# PCIE0_DAT register map
Vendor: Texas Instruments
Registers are 32-bit, read-write, reset 0x0 unless marked. A register's access mark holds for its fields unless they carry their own. Offsets are as the file gives them; [hi:lo] are bit positions; {n}, {i} and the like mark numbered series.

## PCIE0_DAT (part 4 of 6)
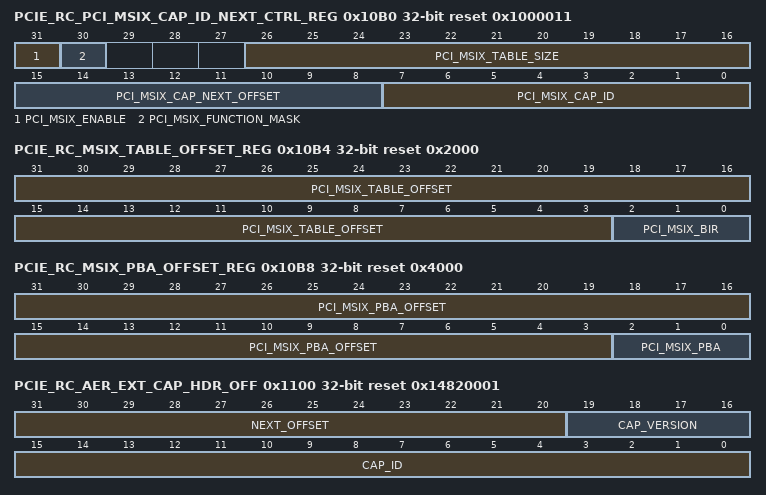
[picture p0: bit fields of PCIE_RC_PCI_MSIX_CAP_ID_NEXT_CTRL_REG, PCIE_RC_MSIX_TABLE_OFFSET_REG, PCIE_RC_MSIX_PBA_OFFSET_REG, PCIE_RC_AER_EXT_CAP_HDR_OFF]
0x10B0 PCIE_RC_PCI_MSIX_CAP_ID_NEXT_CTRL_REG access per field reset 0x1000011 — MSI-X Capability ID, Next Pointer, Control Registers. For a description of this standard PCIe register, see the PCI Express Specification.
  [31] PCI_MSIX_ENABLE rw — MSI-X Enable For a description of this standard PCIe register field, see the PCI Express Specification
  [30] PCI_MSIX_FUNCTION_MASK rw — Function Mask For a description of this standard PCIe register field, see the PCI Express Specification Note: The access attributes of this field are as follows: - Dbi: R/W
  [26:16] PCI_MSIX_TABLE_SIZE ro — MSI-X Table Size For a description of this standard PCIe register field, see the PCI Express Specification SRIOV Note: All VFs in a single PF have the same value for 'MSI-X Table Size' [PCI_MSIX_TABLE_SIZE field in VF_PCI_MSIX_CAP_ID_NEXT_CTRL_REG] To write this common value, you must perform a DBI_CS2 write [that is, assert the dbi_cs2 input, or the CS2 address bit for the AXI bridge] while accessing the PCI_MSIX_TABLE_SIZE field in the PF
  [15:8] PCI_MSIX_CAP_NEXT_OFFSET ro — MSI-X Next Capability Pointer For a description of this standard PCIe register field, see the PCI Express Specification Note: The access attributes of this field are as follows: - Dbi: if [DBI_RO_WR_EN == 1] then R/W else R Note: This register field is sticky
  [7:0] PCI_MSIX_CAP_ID ro — MSI-X Capability ID For a description of this standard PCIe register field, see the PCI Express Specification
0x10B4 PCIE_RC_MSIX_TABLE_OFFSET_REG ro reset 0x2000 — MSI-X Table Offset and BIR Register. For a description of this standard PCIe register, see the PCI Express Specification.
  [31:3] PCI_MSIX_TABLE_OFFSET — MSI-X Table Offset For a description of this standard PCIe register field, see the PCI Express Specification Note: The access attributes of this field are as follows: - Dbi: if [DBI_RO_WR_EN == 1 &amp;&amp; MSIX_CAP_ENABLE=1] then R/W else R Note: This register field is sticky
  [2:0] PCI_MSIX_BIR — MSI-X Table Bar Indicator Register Field For a description of this standard PCIe register field, see the PCI Express Specification Note: The access attributes of this field are as follows: - Dbi: if [DBI_RO_WR_EN == 1 &amp;&amp; MSIX_CAP_ENABLE=1 ] then R/W else R Note: This register field is sticky
0x10B8 PCIE_RC_MSIX_PBA_OFFSET_REG ro reset 0x4000 — MSI-X PBA Offset and BIR Register. For a description of this standard PCIe register, see the PCI Express Specification.
  [31:3] PCI_MSIX_PBA_OFFSET — MSI-X PBA Offset For a description of this standard PCIe register field, see the PCI Express Specification Note: The access attributes of this field are as follows: - Dbi: if [DBI_RO_WR_EN == 1 &amp;&amp; MSIX_CAP_ENABLE=1] then R/W else R Note: This register field is sticky
  [2:0] PCI_MSIX_PBA — MSI-X PBA BIR For a description of this standard PCIe register field, see the PCI Express Specification Note: The access attributes of this field are as follows: - Dbi: if [DBI_RO_WR_EN == 1 &amp;&amp; MSIX_CAP_ENABLE=1] then R/W else R Note: This register field is sticky
0x1100 PCIE_RC_AER_EXT_CAP_HDR_OFF ro reset 0x14820001 — Advanced Error Reporting Extended Capability Header. For a description of this standard PCIe register, see the PCI Express Specification.
  [31:20] NEXT_OFFSET — Next Capability Offset For a description of this standard PCIe register field, see the PCI Express Specification Note: The access attributes of this field are as follows: - Dbi: if [DBI_RO_WR_EN == 1] then R/W[sticky] else R[sticky] Note: This register field is sticky
  [19:16] CAP_VERSION — Capability Version For a description of this standard PCIe register field, see the PCI Express Specification Note: The access attributes of this field are as follows: - Dbi: if [DBI_RO_WR_EN == 1] then R/W[sticky] else R[sticky] Note: This register field is sticky
  [15:0] CAP_ID — AER Extended Capability ID For a description of this standard PCIe register field, see the PCI Express Specification Note: The access attributes of this field are as follows: - Dbi: if [DBI_RO_WR_EN == 1] then R/W[sticky] else R[sticky] Note: This register field is sticky
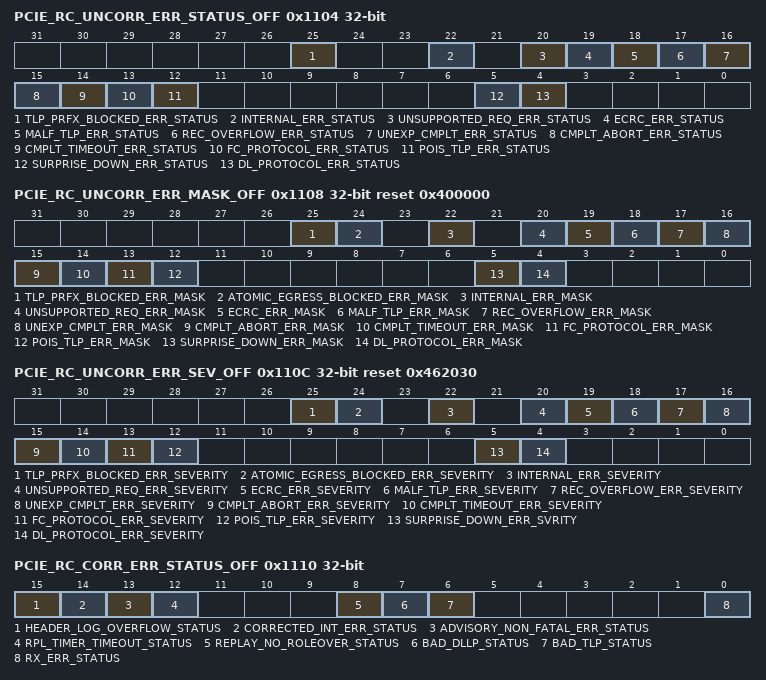
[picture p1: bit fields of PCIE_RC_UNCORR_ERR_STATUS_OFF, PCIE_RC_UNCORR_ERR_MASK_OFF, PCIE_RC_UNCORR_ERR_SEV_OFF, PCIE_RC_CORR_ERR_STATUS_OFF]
0x1104 PCIE_RC_UNCORR_ERR_STATUS_OFF access not given — Uncorrectable Error Status Register. For a description of this standard PCIe register, see the PCI Express Specification.
  [25] TLP_PRFX_BLOCKED_ERR_STATUS — TLP Prefix Blocked Error Status For a description of this standard PCIe register field, see the PCI Express Specification Note: Not supported (access RW1C)
  [22] INTERNAL_ERR_STATUS — Uncorrectable Internal Error Status For a description of this standard PCIe register field, see the PCI Express Specification The controller sets this bit when your application asserts app_err_bus[9] It does not set this bit when it detects internal uncorrectable internal errors such as parity and ECC failures You should use the outputs from these errors to drive the app_err_bus[9] input (access RW1C)
  [20] UNSUPPORTED_REQ_ERR_STATUS — Unsupported Request Error Status For a description of this standard PCIe register field, see the PCI Express Specification (access RW1C)
  [19] ECRC_ERR_STATUS — ECRC Error Status For a description of this standard PCIe register field, see the PCI Express Specification (access RW1C)
  [18] MALF_TLP_ERR_STATUS — Malformed TLP Status For a description of this standard PCIe register field, see the PCI Express Specification (access RW1C)
  [17] REC_OVERFLOW_ERR_STATUS — Receiver Overflow Status For a description of this standard PCIe register field, see the PCI Express Specification (access RW1C)
  [16] UNEXP_CMPLT_ERR_STATUS — Unexpected Completion Status For a description of this standard PCIe register field, see the PCI Express Specification (access RW1C)
  [15] CMPLT_ABORT_ERR_STATUS — Completer Abort Status For a description of this standard PCIe register field, see the PCI Express Specification (access RW1C)
  [14] CMPLT_TIMEOUT_ERR_STATUS — Completion Timeout Status For a description of this standard PCIe register field, see the PCI Express Specification (access RW1C)
  [13] FC_PROTOCOL_ERR_STATUS — Flow Control Protocol Error Status For a description of this standard PCIe register field, see the PCI Express Specification (access RW1C)
  [12] POIS_TLP_ERR_STATUS — Poisoned TLP Status For a description of this standard PCIe register field, see the PCI Express Specification (access RW1C)
  [5] SURPRISE_DOWN_ERR_STATUS — Surprise Down Error Status [Optional] For a description of this standard PCIe register field, see the PCI Express Specification (access RW1C)
  [4] DL_PROTOCOL_ERR_STATUS — Data Link Protocol Error Status For a description of this standard PCIe register field, see the PCI Express Specification (access RW1C)
0x1108 PCIE_RC_UNCORR_ERR_MASK_OFF access per field reset 0x400000 — Uncorrectable Error Mask Register. For a description of this standard PCIe register, see the PCI Express Specification.
  [25] TLP_PRFX_BLOCKED_ERR_MASK ro — TLP Prefix Blocked Error Mask For a description of this standard PCIe register field, see the PCI Express Specification Note: Not supported Note: The access attributes of this field are as follows: - Dbi: R/W [sticky] Note: This register field is sticky
  [24] ATOMIC_EGRESS_BLOCKED_ERR_MASK ro — AtomicOp Egress Block Mask [Optional] For a description of this standard PCIe register field, see the PCI Express Specification Note: The access attributes of this field are as follows: - Dbi: R/W [sticky] Note: This register field is sticky
  [22] INTERNAL_ERR_MASK rw — Uncorrectable Internal Error Mask [Optional] For a description of this standard PCIe register field, see the PCI Express Specification Note: This register field is sticky
  [20] UNSUPPORTED_REQ_ERR_MASK rw — Unsupported Request Error Mask For a description of this standard PCIe register field, see the PCI Express Specification Note: This register field is sticky
  [19] ECRC_ERR_MASK rw — ECRC Error Mask [Optional] For a description of this standard PCIe register field, see the PCI Express Specification Note: The access attributes of this field are as follows: - Dbi: R/W [sticky] Note: This register field is sticky
  [18] MALF_TLP_ERR_MASK rw — Malformed TLP Mask For a description of this standard PCIe register field, see the PCI Express Specification Note: This register field is sticky
  [17] REC_OVERFLOW_ERR_MASK rw — Receiver Overflow Mask [Optional] For a description of this standard PCIe register field, see the PCI Express Specification Note: This register field is sticky
  [16] UNEXP_CMPLT_ERR_MASK rw — Unexpected Completion Mask For a description of this standard PCIe register field, see the PCI Express Specification Note: This register field is sticky
  [15] CMPLT_ABORT_ERR_MASK rw — Completer Abort Error Mask [Optional] For a description of this standard PCIe register field, see the PCI Express Specification Note: This register field is sticky
  [14] CMPLT_TIMEOUT_ERR_MASK rw — Completion Timeout Error Mask For a description of this standard PCIe register field, see the PCI Express Specification Note: This register field is sticky
  [13] FC_PROTOCOL_ERR_MASK rw — Flow Control Protocol Error Mask For a description of this standard PCIe register field, see the PCI Express Specification Note: This register field is sticky
  [12] POIS_TLP_ERR_MASK rw — Poisoned TLP Error Mask For a description of this standard PCIe register field, see the PCI Express Specification Note: This register field is sticky
  [5] SURPRISE_DOWN_ERR_MASK ro — Surprise Down Error Mask For a description of this standard PCIe register field, see the PCI Express Specification Note: The access attributes of this field are as follows: - Dbi: LINK_CAPABILITIES_REGPCIE_CAP_SURPRISE_DOWN_ERR_REP_CAP ? RW : RO Note: This register field is sticky
  [4] DL_PROTOCOL_ERR_MASK rw — Data Link Protocol Error Mask For a description of this standard PCIe register field, see the PCI Express Specification Note: This register field is sticky
0x110C PCIE_RC_UNCORR_ERR_SEV_OFF access per field reset 0x462030 — Uncorrectable Error Severity Register. For a description of this standard PCIe register, see the PCI Express Specification.
  [25] TLP_PRFX_BLOCKED_ERR_SEVERITY ro — TLP Prefix Blocked Error Severity [Optional] For a description of this standard PCIe register field, see the PCI Express Specification Note: Not supported Note: The access attributes of this field are as follows: - Dbi: R/W [sticky] Note: This register field is sticky
  [24] ATOMIC_EGRESS_BLOCKED_ERR_SEVERITY ro — AtomicOp Egress Blocked Severity [Optional] For a description of this standard PCIe register field, see the PCI Express Specification Note: The access attributes of this field are as follows: - Dbi: R/W [sticky] Note: This register field is sticky
  [22] INTERNAL_ERR_SEVERITY rw — Uncorrectable Internal Error Severity [Optional] For a description of this standard PCIe register field, see the PCI Express Specification Note: This register field is sticky
  [20] UNSUPPORTED_REQ_ERR_SEVERITY rw — Unsupported Request Error Severity For a description of this standard PCIe register field, see the PCI Express Specification Note: This register field is sticky
  [19] ECRC_ERR_SEVERITY rw — ECRC Error Severity [Optional] For a description of this standard PCIe register field, see the PCI Express Specification Note: The access attributes of this field are as follows: - Dbi: R/W [sticky] Note: This register field is sticky
  [18] MALF_TLP_ERR_SEVERITY rw — Malformed TLP Severity For a description of this standard PCIe register field, see the PCI Express Specification Note: This register field is sticky
  [17] REC_OVERFLOW_ERR_SEVERITY rw — Receiver Overflow Error Severity [Optional] For a description of this standard PCIe register field, see the PCI Express Specification Note: This register field is sticky
  [16] UNEXP_CMPLT_ERR_SEVERITY rw — Unexpected Completion Error Severity For a description of this standard PCIe register field, see the PCI Express Specification Note: This register field is sticky
  [15] CMPLT_ABORT_ERR_SEVERITY rw — Completer Abort Error Severity [Optional] For a description of this standard PCIe register field, see the PCI Express Specification Note: This register field is sticky
  [14] CMPLT_TIMEOUT_ERR_SEVERITY rw — Completion Timeout Error Severity For a description of this standard PCIe register field, see the PCI Express Specification Note: This register field is sticky
  [13] FC_PROTOCOL_ERR_SEVERITY rw — Flow Control Protocol Error Severity [Optional] For a description of this standard PCIe register field, see the PCI Express Specification Note: This register field is sticky
  [12] POIS_TLP_ERR_SEVERITY rw — Poisoned TLP Severity For a description of this standard PCIe register field, see the PCI Express Specification Note: This register field is sticky
  [5] SURPRISE_DOWN_ERR_SVRITY ro — Surprise Down Error Severity [Optional] For a description of this standard PCIe register field, see the PCI Express Specification Note: The access attributes of this field are as follows: - Dbi: LINK_CAPABILITIES_REGPCIE_CAP_SURPRISE_DOWN_ERR_REP_CAP ? RW : RO Note: This register field is sticky
  [4] DL_PROTOCOL_ERR_SEVERITY rw — Data Link Protocol Error Severity For a description of this standard PCIe register field, see the PCI Express Specification Note: This register field is sticky
0x1110 PCIE_RC_CORR_ERR_STATUS_OFF access not given — Correctable Error Status Register. For a description of this standard PCIe register, see the PCI Express Specification.
  [15] HEADER_LOG_OVERFLOW_STATUS — Header Log Overflow Error Status [Optional] For a description of this standard PCIe register field, see the PCI Express Specification (access RW1C)
  [14] CORRECTED_INT_ERR_STATUS — Corrected Internal Error Status [Optional] For a description of this standard PCIe register field, see the PCI Express Specification (access RW1C)
  [13] ADVISORY_NON_FATAL_ERR_STATUS — Advisory Non-Fatal Error Status For a description of this standard PCIe register field, see the PCI Express Specification (access RW1C)
  [12] RPL_TIMER_TIMEOUT_STATUS — Replay Timer Timeout Status For a description of this standard PCIe register field, see the PCI Express Specification (access RW1C)
  [8] REPLAY_NO_ROLEOVER_STATUS — REPLAY_NUM Rollover Status For a description of this standard PCIe register field, see the PCI Express Specification (access RW1C)
  [7] BAD_DLLP_STATUS — Bad DLLP Status For a description of this standard PCIe register field, see the PCI Express Specification (access RW1C)
  [6] BAD_TLP_STATUS — Bad TLP Status For a description of this standard PCIe register field, see the PCI Express Specification (access RW1C)
  [0] RX_ERR_STATUS — Receiver Error Status [Optional] For a description of this standard PCIe register field, see the PCI Express Specification (access RW1C)
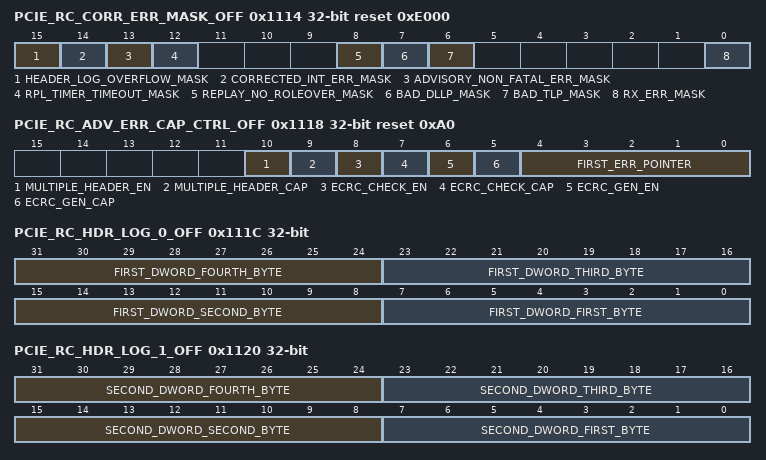
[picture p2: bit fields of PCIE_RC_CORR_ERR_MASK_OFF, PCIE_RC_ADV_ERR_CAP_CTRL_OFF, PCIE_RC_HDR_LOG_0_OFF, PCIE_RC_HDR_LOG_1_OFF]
0x1114 PCIE_RC_CORR_ERR_MASK_OFF access per field reset 0xE000 — Correctable Error Mask Register. For a description of this standard PCIe register, see the PCI Express Specification.
  [15] HEADER_LOG_OVERFLOW_MASK rw — Header Log Overflow Error Mask [Optional] For a description of this standard PCIe register field, see the PCI Express Specification Note: This register field is sticky
  [14] CORRECTED_INT_ERR_MASK rw — Corrected Internal Error Mask [Optional] For a description of this standard PCIe register field, see the PCI Express Specification Note: This register field is sticky
  [13] ADVISORY_NON_FATAL_ERR_MASK rw — Advisory Non-Fatal Error Mask For a description of this standard PCIe register field, see the PCI Express Specification Note: This register field is sticky
  [12] RPL_TIMER_TIMEOUT_MASK rw — Replay Timer Timeout Mask For a description of this standard PCIe register field, see the PCI Express Specification Note: This register field is sticky
  [8] REPLAY_NO_ROLEOVER_MASK rw — REPLAY_NUM Rollover Mask For a description of this standard PCIe register field, see the PCI Express Specification Note: This register field is sticky
  [7] BAD_DLLP_MASK rw — Bad DLLP Mask For a description of this standard PCIe register field, see the PCI Express Specification Note: This register field is sticky
  [6] BAD_TLP_MASK rw — Bad TLP Mask For a description of this standard PCIe register field, see the PCI Express Specification Note: This register field is sticky
  [0] RX_ERR_MASK rw — Receiver Error Mask [Optional] For a description of this standard PCIe register field, see the PCI Express Specification Note: This register field is sticky
0x1118 PCIE_RC_ADV_ERR_CAP_CTRL_OFF access per field reset 0xA0 — Advanced Error Capabilities and Control Register. For a description of this standard PCIe register, see the PCI Express Specification.
  [10] MULTIPLE_HEADER_EN ro — Multiple Header Recording Enable For a description of this standard PCIe register field, see the PCI Express Specification Note: This register field is sticky
  [9] MULTIPLE_HEADER_CAP ro — Multiple Header Recording Capable For a description of this standard PCIe register field, see the PCI Express Specification Note: This register field is sticky
  [8] ECRC_CHECK_EN rw — ECRC Check Enable For a description of this standard PCIe register field, see the PCI Express Specification Note: This register field is sticky
  [7] ECRC_CHECK_CAP ro — ECRC Check Capable For a description of this standard PCIe register field, see the PCI Express Specification Note: This register field is sticky
  [6] ECRC_GEN_EN rw — ECRC Generation Enable For a description of this standard PCIe register field, see the PCI Express Specification Note: This register field is sticky
  [5] ECRC_GEN_CAP ro — ECRC Generation Capable For a description of this standard PCIe register field, see the PCI Express Specification Note: This register field is sticky
  [4:0] FIRST_ERR_POINTER ro — First Error Pointer For a description of this standard PCIe register field, see the PCI Express Specification Note: This register field is sticky
0x111C PCIE_RC_HDR_LOG_0_OFF ro — Header Log Register 0. For a description of this standard PCIe register, see the PCI Express Specification.
  [31:24] FIRST_DWORD_FOURTH_BYTE — Byte 3 of Header log register of First 32 bit Data Word For a description of this standard PCIe register field, see the PCI Express Specification Note: This register field is sticky
  [23:16] FIRST_DWORD_THIRD_BYTE — Byte 2 of Header log register of First 32 bit Data Word For a description of this standard PCIe register field, see the PCI Express Specification Note: This register field is sticky
  [15:8] FIRST_DWORD_SECOND_BYTE — Byte 1 of Header log register of First 32 bit Data Word For a description of this standard PCIe register field, see the PCI Express Specification Note: This register field is sticky
  [7:0] FIRST_DWORD_FIRST_BYTE — Byte 0 of Header log register of First 32 bit Data Word For a description of this standard PCIe register field, see the PCI Express Specification Note: This register field is sticky
0x1120 PCIE_RC_HDR_LOG_1_OFF ro — Header Log Register 1. For a description of this standard PCIe register, see the PCI Express Specification.
  [31:24] SECOND_DWORD_FOURTH_BYTE — Byte 3 of Header log register of Second 32 bit Data Word For a description of this standard PCIe register field, see the PCI Express Specification Note: This register field is sticky
  [23:16] SECOND_DWORD_THIRD_BYTE — Byte 2 of Header log register of Second 32 bit Data Word For a description of this standard PCIe register field, see the PCI Express Specification Note: This register field is sticky
  [15:8] SECOND_DWORD_SECOND_BYTE — Byte 1 of Header log register of Second 32 bit Data Word For a description of this standard PCIe register field, see the PCI Express Specification Note: This register field is sticky
  [7:0] SECOND_DWORD_FIRST_BYTE — Byte 0 of Header log register of Second 32 bit Data Word For a description of this standard PCIe register field, see the PCI Express Specification Note: This register field is sticky
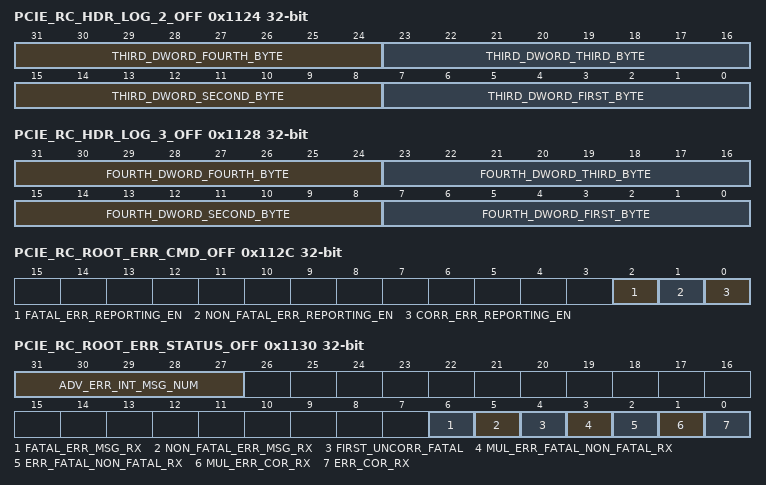
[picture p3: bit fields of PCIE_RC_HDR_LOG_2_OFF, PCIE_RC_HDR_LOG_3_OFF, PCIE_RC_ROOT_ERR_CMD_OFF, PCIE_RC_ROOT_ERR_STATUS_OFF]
0x1124 PCIE_RC_HDR_LOG_2_OFF ro — Header Log Register 2. For a description of this standard PCIe register, see the PCI Express Specification.
  [31:24] THIRD_DWORD_FOURTH_BYTE — Byte 3 of Header log register of Third 32 bit Data Word For a description of this standard PCIe register field, see the PCI Express Specification Note: This register field is sticky
  [23:16] THIRD_DWORD_THIRD_BYTE — Byte 2 of Header log register of Third 32 bit Data Word For a description of this standard PCIe register field, see the PCI Express Specification Note: This register field is sticky
  [15:8] THIRD_DWORD_SECOND_BYTE — Byte 1 of Header log register of Third 32 bit Data Word For a description of this standard PCIe register field, see the PCI Express Specification Note: This register field is sticky
  [7:0] THIRD_DWORD_FIRST_BYTE — Byte 0 of Header log register of Third 32 bit Data Word For a description of this standard PCIe register field, see the PCI Express Specification Note: This register field is sticky
0x1128 PCIE_RC_HDR_LOG_3_OFF ro — Header Log Register 3. For a description of this standard PCIe register, see the PCI Express Specification.
  [31:24] FOURTH_DWORD_FOURTH_BYTE — Byte 3 of Header log register of Fourth 32 bit Data Word For a description of this standard PCIe register field, see the PCI Express Specification Note: This register field is sticky
  [23:16] FOURTH_DWORD_THIRD_BYTE — Byte 2 of Header log register of Fourth 32 bit Data Word For a description of this standard PCIe register field, see the PCI Express Specification Note: This register field is sticky
  [15:8] FOURTH_DWORD_SECOND_BYTE — Byte 1 of Header log register of Fourth 32 bit Data Word For a description of this standard PCIe register field, see the PCI Express Specification Note: This register field is sticky
  [7:0] FOURTH_DWORD_FIRST_BYTE — Byte 0 of Header log register of Fourth 32 bit Data Word For a description of this standard PCIe register field, see the PCI Express Specification Note: This register field is sticky
0x112C PCIE_RC_ROOT_ERR_CMD_OFF access per field — Root Error Command Register. For a description of this standard PCIe register, see the PCI Express Specification.
  [2] FATAL_ERR_REPORTING_EN rw — Fatal Error Reporting Enable For a description of this standard PCIe register field, see the PCI Express Specification
  [1] NON_FATAL_ERR_REPORTING_EN rw — Non-Fatal Error Reporting Enable For a description of this standard PCIe register field, see the PCI Express Specification
  [0] CORR_ERR_REPORTING_EN rw — Correctable Error Reporting Enable For a description of this standard PCIe register field, see the PCI Express Specification
0x1130 PCIE_RC_ROOT_ERR_STATUS_OFF access not given — Root Error Status Register. For a description of this standard PCIe register, see the PCI Express Specification.
  [31:27] ADV_ERR_INT_MSG_NUM ro — Advanced Error Interrupt Message Number For a description of this standard PCIe register field, see the PCI Express Specification Note: The access attributes of this field are as follows: - Dbi: if [DBI_RO_WR_EN == 1] then R/W[sticky] else R[sticky] Note: This register field is sticky
  [6] FATAL_ERR_MSG_RX — One or more Fatal Error Messages Received For a description of this standard PCIe register field, see the PCI Express Specification (access RW1C)
  [5] NON_FATAL_ERR_MSG_RX — One or more Non-Fatal Error Messages Received For a description of this standard PCIe register field, see the PCI Express Specification (access RW1C)
  [4] FIRST_UNCORR_FATAL — First Uncorrectable Error is Fatal For a description of this standard PCIe register field, see the PCI Express Specification (access RW1C)
  [3] MUL_ERR_FATAL_NON_FATAL_RX — Multiple Fatal or Non-Fatal Errors Received For a description of this standard PCIe register field, see the PCI Express Specification (access RW1C)
  [2] ERR_FATAL_NON_FATAL_RX — Fatal or Non-Fatal Error Received For a description of this standard PCIe register field, see the PCI Express Specification (access RW1C)
  [1] MUL_ERR_COR_RX — Multiple Correctable Errors Received For a description of this standard PCIe register field, see the PCI Express Specification (access RW1C)
  [0] ERR_COR_RX — Correctable Error Received For a description of this standard PCIe register field, see the PCI Express Specification (access RW1C)
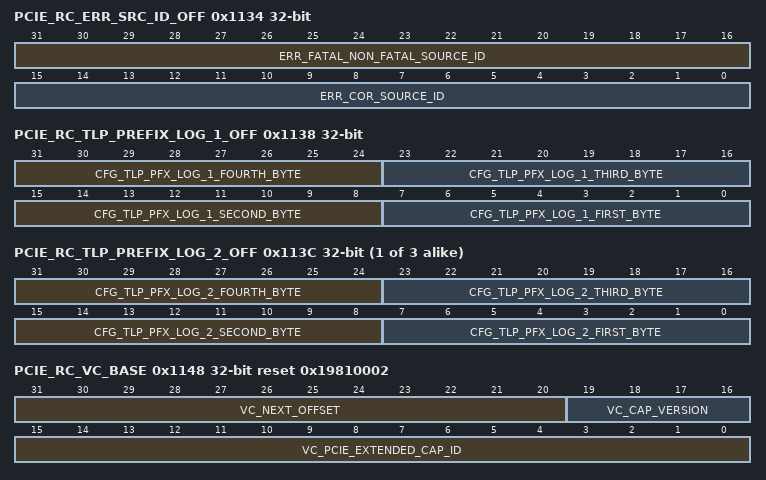
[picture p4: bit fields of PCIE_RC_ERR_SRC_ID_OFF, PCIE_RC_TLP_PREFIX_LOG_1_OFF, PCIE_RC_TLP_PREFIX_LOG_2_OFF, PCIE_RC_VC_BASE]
0x1134 PCIE_RC_ERR_SRC_ID_OFF ro — Error Source Identification Register. For a description of this standard PCIe register, see the PCI Express Specification.
  [31:16] ERR_FATAL_NON_FATAL_SOURCE_ID — Source of Fatal/Non-Fatal Error For a description of this standard PCIe register field, see the PCI Express Specification Note: This register field is sticky
  [15:0] ERR_COR_SOURCE_ID — Source of Correctable Error For a description of this standard PCIe register field, see the PCI Express Specification Note: This register field is sticky
0x1138 PCIE_RC_TLP_PREFIX_LOG_1_OFF ro — TLP Prefix Log Register 1. For a description of this standard PCIe register, see the PCI Express Specification.
  [31:24] CFG_TLP_PFX_LOG_1_FOURTH_BYTE — Byte 3 of Error TLP Prefix Log 1 For a description of this standard PCIe register field, see the PCI Express Specification Note: This register field is sticky
  [23:16] CFG_TLP_PFX_LOG_1_THIRD_BYTE — Byte 2 of Error TLP Prefix Log 1 For a description of this standard PCIe register field, see the PCI Express Specification Note: This register field is sticky
  [15:8] CFG_TLP_PFX_LOG_1_SECOND_BYTE — Byte 1 of Error TLP Prefix Log 1 For a description of this standard PCIe register field, see the PCI Express Specification Note: This register field is sticky
  [7:0] CFG_TLP_PFX_LOG_1_FIRST_BYTE — Byte 0 of Error TLP Prefix Log 1 For a description of this standard PCIe register field, see the PCI Express Specification Note: This register field is sticky
{0x1134+4i} PCIE_RC_TLP_PREFIX_LOG_{i}_OFF ro (i=2..4) — TLP Prefix Log Register {i}. For a description of this standard PCIe register, see the PCI Express Specification.
  [31:24] CFG_TLP_PFX_LOG_{i}_FOURTH_BYTE — Byte 3 Error TLP Prefix Log {i} For a description of this standard PCIe register field, see the PCI Express Specification Note: This register field is sticky
  [23:16] CFG_TLP_PFX_LOG_{i}_THIRD_BYTE — Byte 2 Error TLP Prefix Log {i} For a description of this standard PCIe register field, see the PCI Express Specification Note: This register field is sticky
  [15:8] CFG_TLP_PFX_LOG_{i}_SECOND_BYTE — Byte 1 Error TLP Prefix Log {i} For a description of this standard PCIe register field, see the PCI Express Specification Note: This register field is sticky
  [7:0] CFG_TLP_PFX_LOG_{i}_FIRST_BYTE — Byte 0 Error TLP Prefix Log {i} For a description of this standard PCIe register field, see the PCI Express Specification Note: This register field is sticky
0x1148 PCIE_RC_VC_BASE ro reset 0x19810002 — VC Extended Capability Header. For a description of this standard PCIe register, see the PCI Express Specification.
  [31:20] VC_NEXT_OFFSET — Next Capability Offset For a description of this standard PCIe register field, see the PCI Express Specification Note: The access attributes of this field are as follows: - Dbi: if [DBI_RO_WR_EN == 1] then R/W[sticky] else R[sticky] Note: This register field is sticky
  [19:16] VC_CAP_VERSION — Capability Version For a description of this standard PCIe register field, see the PCI Express Specification Note: The access attributes of this field are as follows: - Dbi: if [DBI_RO_WR_EN == 1] then R/W[sticky] else R[sticky] Note: This register field is sticky
  [15:0] VC_PCIE_EXTENDED_CAP_ID — VC Extended Capability ID For a description of this standard PCIe register field, see the PCI Express Specification Note: The access attributes of this field are as follows: - Dbi: if [DBI_RO_WR_EN == 1] then R/W[sticky] else R[sticky] Note: This register field is sticky
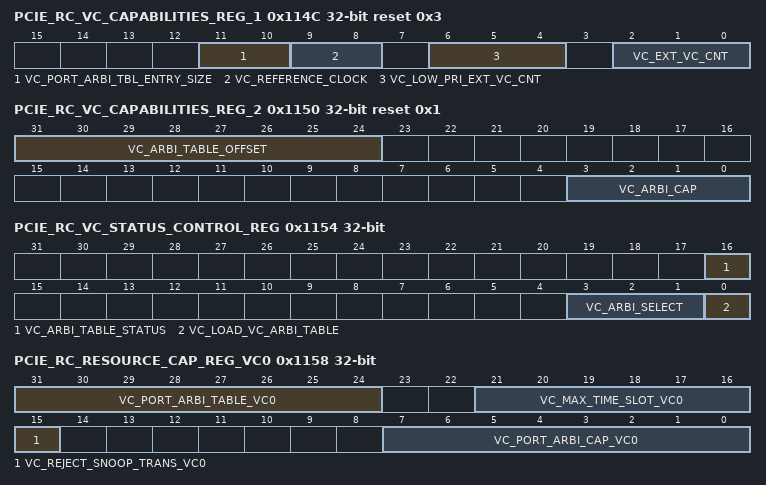
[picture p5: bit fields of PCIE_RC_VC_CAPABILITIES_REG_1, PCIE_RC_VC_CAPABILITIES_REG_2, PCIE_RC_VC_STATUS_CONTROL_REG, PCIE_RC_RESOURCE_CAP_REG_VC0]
0x114C PCIE_RC_VC_CAPABILITIES_REG_1 ro reset 0x3 — Port VC Capability Register 1. For a description of this standard PCIe register, see the PCI Express Specification.
  [11:10] VC_PORT_ARBI_TBL_ENTRY_SIZE — Port Arbitration Table Entry Size For a description of this standard PCIe register field, see the PCI Express Specification
  [9:8] VC_REFERENCE_CLOCK — Reference Clock For a description of this standard PCIe register field, see the PCI Express Specification
  [6:4] VC_LOW_PRI_EXT_VC_CNT — Low Priority Extended VC Count For a description of this standard PCIe register field, see the PCI Express Specification Note: The access attributes of this field are as follows: - Dbi: if [DBI_RO_WR_EN == 1] then R/W else R Note: This register field is sticky
  [2:0] VC_EXT_VC_CNT — Extended VC Count For a description of this standard PCIe register field, see the PCI Express Specification
0x1150 PCIE_RC_VC_CAPABILITIES_REG_2 ro reset 0x1 — Port VC Capability Register 2. For a description of this standard PCIe register, see the PCI Express Specification.
  [31:24] VC_ARBI_TABLE_OFFSET — VC Arbitration Table Offset For a description of this standard PCIe register field, see the PCI Express Specification
  [3:0] VC_ARBI_CAP — VC Arbitration Capability For a description of this standard PCIe register field, see the PCI Express Specification Note: The access attributes of this field are as follows: - Dbi: if [DBI_RO_WR_EN == 1] then R/W else R Note: This register field is sticky
0x1154 PCIE_RC_VC_STATUS_CONTROL_REG access per field — Port VC Control and Status Register. For a description of this standard PCIe register, see the PCI Express Specification.
  [16] VC_ARBI_TABLE_STATUS ro — VC Arbitration Table Status For a description of this standard PCIe register field, see the PCI Express Specification
  [3:1] VC_ARBI_SELECT rw — VC Arbitration Select For a description of this standard PCIe register field, see the PCI Express Specification
  [0] VC_LOAD_VC_ARBI_TABLE ro — Requests Hardware to Load VC Arbitration Table For a description of this standard PCIe register field, see the PCI Express Specification
0x1158 PCIE_RC_RESOURCE_CAP_REG_VC0 ro — VC Resource Capability Register (0). For a description of this standard PCIe register, see the PCI Express Specification.
  [31:24] VC_PORT_ARBI_TABLE_VC0 — Port Arbitration Table Offset For a description of this standard PCIe register field, see the PCI Express Specification
  [21:16] VC_MAX_TIME_SLOT_VC0 — Maximum Time Slots-1 supported For a description of this standard PCIe register field, see the PCI Express Specification Note: The access attributes of this field are as follows: - Dbi: R
  [15] VC_REJECT_SNOOP_TRANS_VC0 — Reject Snoop Transactions For a description of this standard PCIe register field, see the PCI Express Specification Note: The access attributes of this field are as follows: - Dbi: R
  [7:0] VC_PORT_ARBI_CAP_VC0 — Port Arbitration Capability For a description of this standard PCIe register field, see the PCI Express Specification
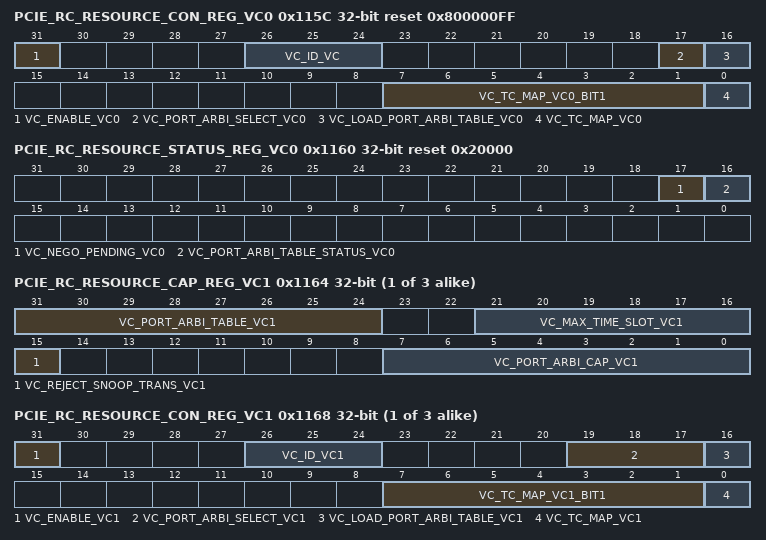
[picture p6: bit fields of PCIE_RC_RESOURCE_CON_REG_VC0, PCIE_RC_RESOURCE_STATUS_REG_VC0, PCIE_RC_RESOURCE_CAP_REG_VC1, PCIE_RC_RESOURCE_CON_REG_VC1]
0x115C PCIE_RC_RESOURCE_CON_REG_VC0 access per field reset 0x800000FF — VC Resource Control Register (0). For a description of this standard PCIe register, see the PCI Express Specification.
  [31] VC_ENABLE_VC0 ro — VC Enable For a description of this standard PCIe register field, see the PCI Express Specification
  [26:24] VC_ID_VC ro — VC ID For a description of this standard PCIe register field, see the PCI Express Specification
  [17] VC_PORT_ARBI_SELECT_VC0 ro — Port Arbitration Select For a description of this standard PCIe register field, see the PCI Express Specification
  [16] VC_LOAD_PORT_ARBI_TABLE_VC0 rw — Load Port Arbitration Table For a description of this standard PCIe register field, see the PCI Express Specification
  [7:1] VC_TC_MAP_VC0_BIT1 rw — Bits 7:1 of TC to VC Mapping For a description of this standard PCIe register field, see the PCI Express Specification
  [0] VC_TC_MAP_VC0 ro — Bit 0 of TC to VC Mapping For a description of this standard PCIe register field, see the PCI Express Specification
0x1160 PCIE_RC_RESOURCE_STATUS_REG_VC0 ro reset 0x20000 — VC Resource Status Register (0). For a description of this standard PCIe register, see the PCI Express Specification.
  [17] VC_NEGO_PENDING_VC0 — VC Negotiation Pending For a description of this standard PCIe register field, see the PCI Express Specification
  [16] VC_PORT_ARBI_TABLE_STATUS_VC0 — Port Arbitration Table Status For a description of this standard PCIe register field, see the PCI Express Specification
{0x1158+0xC*i} PCIE_RC_RESOURCE_CAP_REG_VC{i} ro (i=1..3) — VC Resource Capability Register ({i}). For a description of this standard PCIe register, see the PCI Express Specification.
  [31:24] VC_PORT_ARBI_TABLE_VC{i} — VC{i} Port Arbitration Table Offset For a description of this standard PCIe register field, see the PCI Express Specification
  [21:16] VC_MAX_TIME_SLOT_VC{i} — VC{i} Maximum Time Slots-1 supported For a description of this standard PCIe register field, see the PCI Express Specification Note: The access attributes of this field are as follows: - Dbi: R
  [15] VC_REJECT_SNOOP_TRANS_VC{i} — VC{i} Reject Snoop Transactions For a description of this standard PCIe register field, see the PCI Express Specification Note: The access attributes of this field are as follows: - Dbi: R
  [7:0] VC_PORT_ARBI_CAP_VC{i} — VC{i} Port Arbitration Capability For a description of this standard PCIe register field, see the PCI Express Specification
{0x115C+0xC*i} PCIE_RC_RESOURCE_CON_REG_VC{i} access per field (i=1..3) — VC Resource Control Register ({i}). For a description of this standard PCIe register, see the PCI Express Specification.
  [31] VC_ENABLE_VC{i} rw — VC{i} VC Enable For a description of this standard PCIe register field, see the PCI Express Specification
  [26:24] VC_ID_VC{i} rw — VC{i} VC ID For a description of this standard PCIe register field, see the PCI Express Specification
  [19:17] VC_PORT_ARBI_SELECT_VC{i} ro — VC{i} Port Arbitration Select For a description of this standard PCIe register field, see the PCI Express Specification
  [16] VC_LOAD_PORT_ARBI_TABLE_VC{i} rw — VC{i} Load Port Arbitration Table For a description of this standard PCIe register field, see the PCI Express Specification
  [7:1] VC_TC_MAP_VC{i}_BIT1 rw — VC{i} Bits 7:1 of TC to VC Mapping For a description of this standard PCIe register field, see the PCI Express Specification
  [0] VC_TC_MAP_VC{i} ro — VC{i} Bit 0 of TC to VC Mapping For a description of this standard PCIe register field, see the PCI Express Specification
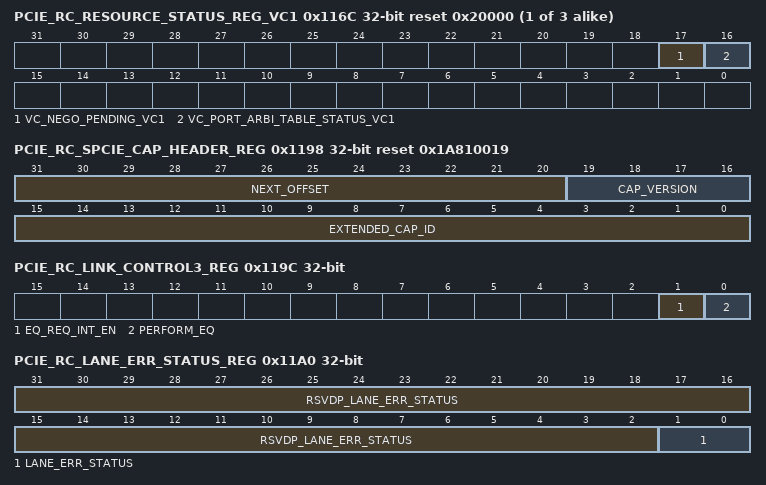
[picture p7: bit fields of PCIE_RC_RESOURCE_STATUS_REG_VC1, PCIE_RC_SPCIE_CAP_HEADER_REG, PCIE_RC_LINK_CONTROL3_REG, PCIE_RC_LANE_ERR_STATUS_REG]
{0x1160+0xC*i} PCIE_RC_RESOURCE_STATUS_REG_VC{i} ro reset 0x20000 (i=1..3) — VC Resource Status Register ({i}). For a description of this standard PCIe register, see the PCI Express Specification.
  [17] VC_NEGO_PENDING_VC{i} — VC{i} VC Negotiation Pending For a description of this standard PCIe register field, see the PCI Express Specification
  [16] VC_PORT_ARBI_TABLE_STATUS_VC{i} — VC{i} Port Arbitration Table Status For a description of this standard PCIe register field, see the PCI Express Specification
0x1198 PCIE_RC_SPCIE_CAP_HEADER_REG ro reset 0x1A810019 — SPCIE Capability Header. For a description of this standard PCIe register, see the PCI Express Specification.
  [31:20] NEXT_OFFSET — Next Capability Offset For a description of this standard PCIe register field, see the PCI Express Specification Note: The access attributes of this field are as follows: - Dbi: if [DBI_RO_WR_EN == 1] then R/W[sticky] else R[sticky] Note: This register field is sticky
  [19:16] CAP_VERSION — Capability Version For a description of this standard PCIe register field, see the PCI Express Specification Note: The access attributes of this field are as follows: - Dbi: if [DBI_RO_WR_EN == 1] then R/W[sticky] else R[sticky] Note: This register field is sticky
  [15:0] EXTENDED_CAP_ID — Secondary PCI Express Extended Capability ID For a description of this standard PCIe register field, see the PCI Express Specification Note: The access attributes of this field are as follows: - Dbi: if [DBI_RO_WR_EN == 1] then R/W[sticky] else R[sticky] Note: This register field is sticky
0x119C PCIE_RC_LINK_CONTROL3_REG access per field — Link Control 3 Register. For a description of this standard PCIe register, see the PCI Express Specification.
  [1] EQ_REQ_INT_EN rw — Link Equalization Request Interrupt Enable For a description of this standard PCIe register field, see the PCI Express Specification Note: The access attributes of this field are as follows: - Dbi: R/W
  [0] PERFORM_EQ rw — Perform Equalization For a description of this standard PCIe register field, see the PCI Express Specification Note: The access attributes of this field are as follows: - Dbi: R/W
0x11A0 PCIE_RC_LANE_ERR_STATUS_REG access not given — Lane Error Status Register. For a description of this standard PCIe register, see the PCI Express Specification.
  [31:2] RSVDP_LANE_ERR_STATUS ro — Reserved for future use
  [1:0] LANE_ERR_STATUS — Lane Error Status Bits per Lane For a description of this standard PCIe register field, see the PCI Express Specification (access RW1C)
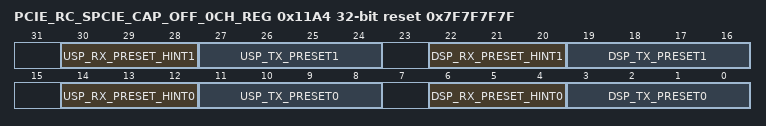
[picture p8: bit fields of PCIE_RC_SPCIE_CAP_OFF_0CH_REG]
0x11A4 PCIE_RC_SPCIE_CAP_OFF_0CH_REG ro reset 0x7F7F7F7F — Lane Equalization Control Register for lanes 1 and 0. For a description of this standard PCIe register, see the PCI Express Specification.
  [30:28] USP_RX_PRESET_HINT1 — Upstream Port 80 GT/s Receiver Preset Hint 1 The write value is gated with the PCIE_CAP_CROSS_LINK_SUPPORT field of
  [27:24] USP_TX_PRESET1 — Upstream Port 80 GT/s Transmitter Preset 1 The write value is gated with the PCIE_CAP_CROSS_LINK_SUPPORT field of
  [22:20] DSP_RX_PRESET_HINT1 — Downstream Port 80 GT/s Receiver Preset Hint 1 For a description of this standard PCIe register field, see the PCI Express Specification Note: The access attributes of this field are as follows: - Dbi: if [DBI_RO_WR_EN == 1] then R/W[sticky] else R[sticky]
  [19:16] DSP_TX_PRESET1 — Downstream Port 80 GT/s Transmitter Preset 1 For a description of this standard PCIe register field, see the PCI Express Specification Note: The access attributes of this field are as follows: - Dbi: if [DBI_RO_WR_EN == 1] then R/W[sticky] else R[sticky]
  [14:12] USP_RX_PRESET_HINT0 — Upstream Port 80 GT/s Receiver Preset Hint 0 The write value is gated with the PCIE_CAP_CROSS_LINK_SUPPORT field of
  [11:8] USP_TX_PRESET0 — Upstream Port 80 GT/s Transmitter Preset 0 The write value is gated with the PCIE_CAP_CROSS_LINK_SUPPORT field of
  [6:4] DSP_RX_PRESET_HINT0 — Downstream Port 80 GT/s Receiver Preset Hint 0 For a description of this standard PCIe register field, see the PCI Express Specification Note: The access attributes of this field are as follows: - Dbi: if [DBI_RO_WR_EN == 1] then R/W[sticky] else R[sticky]
  [3:0] DSP_TX_PRESET0 — Downstream Port 80 GT/s Transmitter Preset 0 For a description of this standard PCIe register field, see the PCI Express Specification Note: The access attributes of this field are as follows: - Dbi: if [DBI_RO_WR_EN == 1] then R/W[sticky] else R[sticky]
